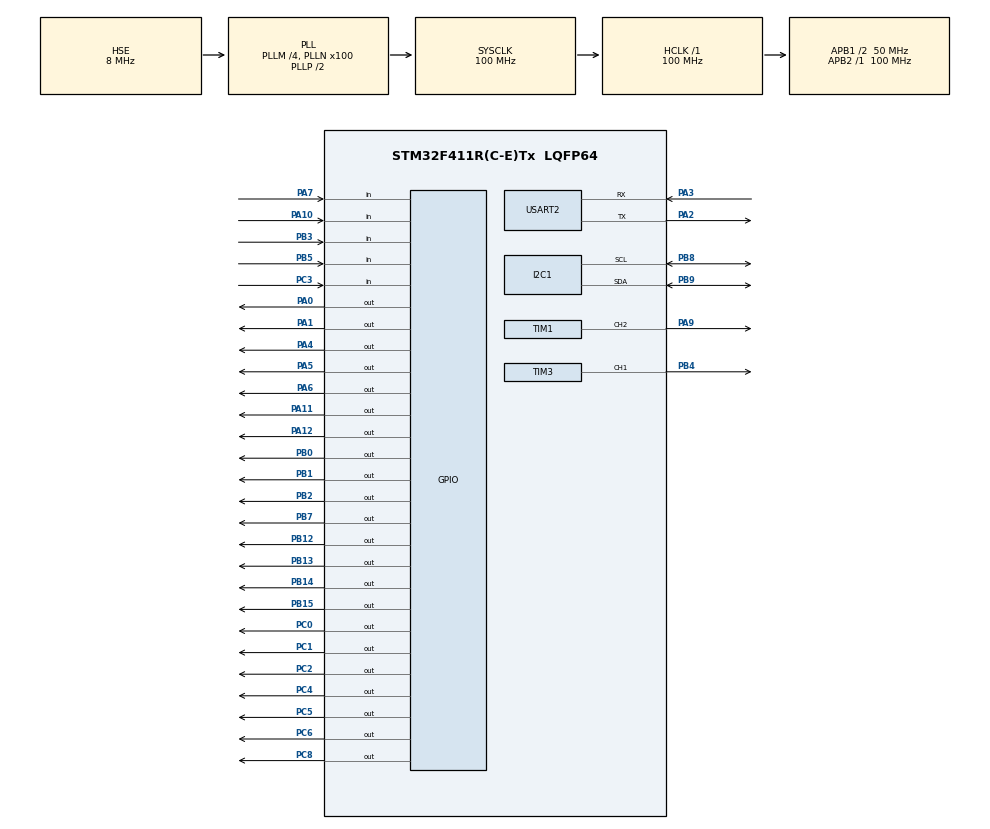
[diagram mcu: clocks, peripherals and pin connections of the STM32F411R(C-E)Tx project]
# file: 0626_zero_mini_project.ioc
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Dma.I2C1_TX.0.Direction=DMA_MEMORY_TO_PERIPH
Dma.I2C1_TX.0.FIFOMode=DMA_FIFOMODE_DISABLE
Dma.I2C1_TX.0.Instance=DMA1_Stream1
Dma.I2C1_TX.0.MemDataAlignment=DMA_MDATAALIGN_BYTE
Dma.I2C1_TX.0.MemInc=DMA_MINC_ENABLE
Dma.I2C1_TX.0.Mode=DMA_NORMAL
Dma.I2C1_TX.0.PeriphDataAlignment=DMA_PDATAALIGN_BYTE
Dma.I2C1_TX.0.PeriphInc=DMA_PINC_DISABLE
Dma.I2C1_TX.0.Priority=DMA_PRIORITY_LOW
Dma.Request0=I2C1_TX
Mcu.Family=STM32F4
Mcu.Name=STM32F411R(C-E)Tx
Mcu.Package=LQFP64
NVIC.DMA1_Stream1_IRQn=true\:0\:0\:false\:false\:true\:false\:true\:true
NVIC.PriorityGroup=NVIC_PRIORITYGROUP_0
NVIC.TIM1_UP_TIM10_IRQn=true\:0\:0\:false\:false\:true\:true\:true\:true
NVIC.TIM2_IRQn=true\:0\:0\:false\:false\:true\:true\:true\:true
NVIC.TIM4_IRQn=true\:0\:0\:false\:false\:true\:true\:true\:true
NVIC.TIM5_IRQn=true\:0\:0\:false\:false\:true\:true\:true\:true
NVIC.USART2_IRQn=true\:0\:0\:false\:false\:true\:true\:true\:true
PA0-WKUP.Signal=GPIO_Output
PA1.Signal=GPIO_Output
PA10.Signal=GPIO_Input
PA11.Signal=GPIO_Output
PA12.Signal=GPIO_Output
PA13.Mode=Serial_Wire
PA13.Signal=SYS_JTMS-SWDIO
PA14.Mode=Serial_Wire
PA14.Signal=SYS_JTCK-SWCLK
PA2.Mode=Asynchronous
PA2.Signal=USART2_TX
PA3.Mode=Asynchronous
PA3.Signal=USART2_RX
PA4.Signal=GPIO_Output
PA5.Signal=GPIO_Output
PA6.Signal=GPIO_Output
PA7.Signal=GPIO_Input
PA9.Signal=S_TIM1_CH2
PB0.Signal=GPIO_Output
PB1.Signal=GPIO_Output
PB12.Signal=GPIO_Output
PB13.Signal=GPIO_Output
PB14.Signal=GPIO_Output
PB15.Signal=GPIO_Output
PB2.Signal=GPIO_Output
PB3.Signal=GPIO_Input
PB4.Signal=S_TIM3_CH1
PB5.Signal=GPIO_Input
PB7.Signal=GPIO_Output
PB8.Mode=I2C
PB8.Signal=I2C1_SCL
PB9.Mode=I2C
PB9.Signal=I2C1_SDA
PC0.Signal=GPIO_Output
PC1.Signal=GPIO_Output
PC2.Signal=GPIO_Output
PC3.Signal=GPIO_Input
PC4.Signal=GPIO_Output
PC5.Signal=GPIO_Output
PC6.Signal=GPIO_Output
PC8.Signal=GPIO_Output
PH0\ -\ OSC_IN.Mode=HSE-External-Oscillator
PH0\ -\ OSC_IN.Signal=RCC_OSC_IN
PH1\ -\ OSC_OUT.Mode=HSE-External-Oscillator
PH1\ -\ OSC_OUT.Signal=RCC_OSC_OUT
ProjectManager.HeapSize=0x200
ProjectManager.StackSize=0x400
ProjectManager.TargetToolchain=STM32CubeIDE
RCC.48MHZClocksFreq_Value=50000000
RCC.AHBFreq_Value=100000000
RCC.APB1CLKDivider=RCC_HCLK_DIV2
RCC.APB1Freq_Value=50000000
RCC.APB1TimFreq_Value=100000000
RCC.APB2Freq_Value=100000000
RCC.APB2TimFreq_Value=100000000
RCC.CortexFreq_Value=100000000
RCC.FLatency-AdvancedSettings=FLASH_LATENCY_3
RCC.HCLKFreq_Value=100000000
RCC.HSE_VALUE=8000000
RCC.HSI_VALUE=16000000
RCC.LSE_VALUE=32768
RCC.PLLM=4
RCC.PLLN=100
RCC.PLLSourceVirtual=RCC_PLLSOURCE_HSE
RCC.SYSCLKFreq_VALUE=100000000
RCC.SYSCLKSource=RCC_SYSCLKSOURCE_PLLCLK
RCC.VCOOutputFreq_Value=200000000
SH.S_TIM1_CH2.0=TIM1_CH2,PWM Generation2 CH2
SH.S_TIM3_CH1.0=TIM3_CH1,PWM Generation1 CH1
TIM1.AutoReloadPreload=TIM_AUTORELOAD_PRELOAD_ENABLE
TIM1.Channel-PWM\ Generation2\ CH2=TIM_CHANNEL_2
TIM1.Period=100-1
TIM1.Prescaler=100-1
TIM1.Pulse-PWM\ Generation2\ CH2=5000-1
TIM10.Period=30000
TIM10.Prescaler=100-1
TIM11.Period=5000-1
TIM11.Prescaler=10000-1
TIM2.Period=1000-1
TIM2.Prescaler=100-1
TIM3.AutoReloadPreload=TIM_AUTORELOAD_PRELOAD_ENABLE
TIM3.Channel-PWM\ Generation1\ CH1=TIM_CHANNEL_1
TIM3.Period=1000-1
TIM3.Prescaler=100-1
TIM3.Pulse-PWM\ Generation1\ CH1=500-1
TIM4.Period=65535
TIM4.Prescaler=100-1
TIM5.Period=100000-1
TIM5.Prescaler=100-1
USART2.VirtualMode=VM_ASYNC
VP_TIM10_VS_ClockSourceINT.Mode=Enable_Timer
VP_TIM11_VS_ClockSourceINT.Mode=Enable_Timer
VP_TIM1_VS_ClockSourceINT.Mode=Internal
VP_TIM2_VS_ClockSourceINT.Mode=Internal
VP_TIM3_VS_ClockSourceINT.Mode=Internal
VP_TIM4_VS_ClockSourceINT.Mode=Internal
VP_TIM5_VS_ClockSourceINT.Mode=Internal
board=NUCLEO-F411RE

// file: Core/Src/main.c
/* USER CODE BEGIN Header */
/**
  ******************************************************************************
  * @file           : main.c
  * @brief          : Main program body
  ******************************************************************************
  * @attention
  *
  * Copyright (c) 2025 STMicroelectronics.
  * All rights reserved.
  *
  * This software is licensed under terms that can be found in the LICENSE file
  * in the root directory of this software component.
  * If no LICENSE file comes with this software, it is provided AS-IS.
  *
  ******************************************************************************
  */
/* USER CODE END Header */
#include "main.h"
#include "dma.h"
#include "i2c.h"
#include "tim.h"
#include "usart.h"
#include "gpio.h"

/* USER CODE BEGIN Includes */
#include "ap_main.h"
/* USER CODE END Includes */

void SystemClock_Config(void);
/* USER CODE BEGIN PFP */
int _write(int file, char* p, int len){
	for(int i=0; i<len; i++){
		ITM_SendChar((*p++));
	}
	return len;
}
/* USER CODE END PFP */

int main(void)
{

  /* MCU Configuration--------------------------------------------------------*/

  /* Reset of all peripherals, Initializes the Flash interface and the Systick. */
  HAL_Init();

  /* Configure the system clock */
  SystemClock_Config();

  /* Initialize all configured peripherals */
  MX_GPIO_Init();
  MX_DMA_Init();
  MX_TIM2_Init();
  MX_USART2_UART_Init();
  MX_I2C1_Init();
  MX_TIM3_Init();
  MX_TIM1_Init();
  MX_TIM4_Init();
  MX_TIM5_Init();
  MX_TIM11_Init();
  MX_TIM10_Init();
  /* USER CODE BEGIN 2 */
  ap_init();
  /* USER CODE END 2 */

  /* Infinite loop */
  /* USER CODE BEGIN WHILE */
  while (1)
  {
	  ap_main();
    /* USER CODE END WHILE */

  }
}

void SystemClock_Config(void)
{
  RCC_OscInitTypeDef RCC_OscInitStruct = {0};
  RCC_ClkInitTypeDef RCC_ClkInitStruct = {0};

  /** Configure the main internal regulator output voltage
  */
  __HAL_RCC_PWR_CLK_ENABLE();
  __HAL_PWR_VOLTAGESCALING_CONFIG(PWR_REGULATOR_VOLTAGE_SCALE1);

  /** Initializes the RCC Oscillators according to the specified parameters
  * in the RCC_OscInitTypeDef structure.
  */
  RCC_OscInitStruct.OscillatorType = RCC_OSCILLATORTYPE_HSE;
  RCC_OscInitStruct.HSEState = RCC_HSE_ON;
  RCC_OscInitStruct.PLL.PLLState = RCC_PLL_ON;
  RCC_OscInitStruct.PLL.PLLSource = RCC_PLLSOURCE_HSE;
  RCC_OscInitStruct.PLL.PLLM = 4;
  RCC_OscInitStruct.PLL.PLLN = 100;
  RCC_OscInitStruct.PLL.PLLP = RCC_PLLP_DIV2;
  RCC_OscInitStruct.PLL.PLLQ = 4;
  if (HAL_RCC_OscConfig(&RCC_OscInitStruct) != HAL_OK)
  {
    Error_Handler();
  }

  /** Initializes the CPU, AHB and APB buses clocks
  */
  RCC_ClkInitStruct.ClockType = RCC_CLOCKTYPE_HCLK|RCC_CLOCKTYPE_SYSCLK
                              |RCC_CLOCKTYPE_PCLK1|RCC_CLOCKTYPE_PCLK2;
  RCC_ClkInitStruct.SYSCLKSource = RCC_SYSCLKSOURCE_PLLCLK;
  RCC_ClkInitStruct.AHBCLKDivider = RCC_SYSCLK_DIV1;
  RCC_ClkInitStruct.APB1CLKDivider = RCC_HCLK_DIV2;
  RCC_ClkInitStruct.APB2CLKDivider = RCC_HCLK_DIV1;

  if (HAL_RCC_ClockConfig(&RCC_ClkInitStruct, FLASH_LATENCY_3) != HAL_OK)
  {
    Error_Handler();
  }
}

void Error_Handler(void)
{
  __disable_irq();
  while (1)
  {
  }
}
